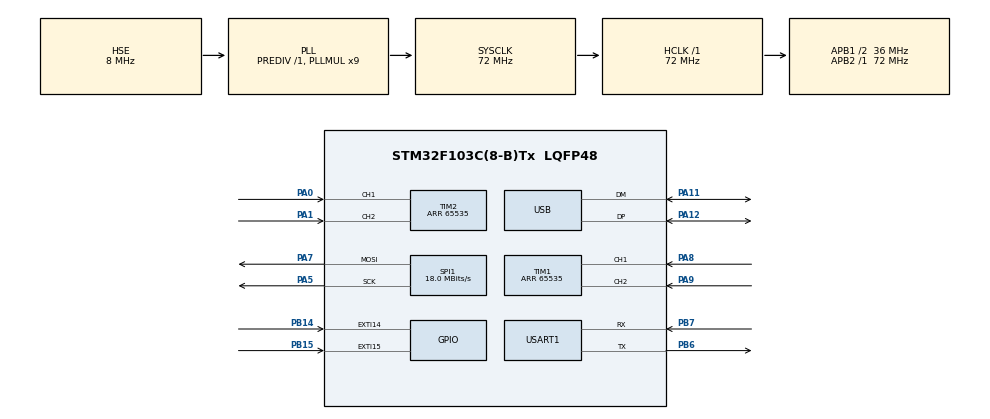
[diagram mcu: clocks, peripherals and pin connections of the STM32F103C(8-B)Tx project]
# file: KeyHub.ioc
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Mcu.Family=STM32F1
Mcu.Name=STM32F103C(8-B)Tx
Mcu.Package=LQFP48
NVIC.EXTI15_10_IRQn=true\:0\:0\:false\:true\:true\:1\:true
NVIC.PriorityGroup=NVIC_PRIORITYGROUP_4
NVIC.USB_HP_CAN1_TX_IRQn=true\:0\:0\:false\:false\:true\:true
NVIC.USB_LP_CAN1_RX0_IRQn=true\:0\:0\:false\:true\:true\:2\:false
PA0-WKUP.GPIO_PuPd=GPIO_PULLUP
PA0-WKUP.Signal=S_TIM2_CH1_ETR
PA1.GPIO_PuPd=GPIO_PULLUP
PA1.Signal=S_TIM2_CH2
PA11.Mode=Device
PA11.Signal=USB_DM
PA12.Mode=Device
PA12.Signal=USB_DP
PA13.Mode=Serial_Wire
PA13.Signal=SYS_JTMS-SWDIO
PA14.Mode=Serial_Wire
PA14.Signal=SYS_JTCK-SWCLK
PA5.Mode=TX_Only_Simplex_Unidirect_Master
PA5.Signal=SPI1_SCK
PA7.Mode=TX_Only_Simplex_Unidirect_Master
PA7.Signal=SPI1_MOSI
PA8.GPIO_PuPd=GPIO_PULLUP
PA8.Signal=S_TIM1_CH1
PA9.GPIO_PuPd=GPIO_PULLUP
PA9.Signal=S_TIM1_CH2
PB14.GPIO_PuPd=GPIO_PULLUP
PB14.Signal=GPXTI14
PB15.GPIO_PuPd=GPIO_PULLUP
PB15.Signal=GPXTI15
PB6.Mode=Asynchronous
PB6.Signal=USART1_TX
PB7.Mode=Asynchronous
PB7.Signal=USART1_RX
PD0-OSC_IN.Mode=HSE-External-Oscillator
PD0-OSC_IN.Signal=RCC_OSC_IN
PD1-OSC_OUT.Mode=HSE-External-Oscillator
PD1-OSC_OUT.Signal=RCC_OSC_OUT
ProjectManager.HeapSize=0x200
ProjectManager.StackSize=0x400
ProjectManager.TargetToolchain=SW4STM32
RCC.AHBFreq_Value=72000000
RCC.APB1CLKDivider=RCC_HCLK_DIV2
RCC.APB1Freq_Value=36000000
RCC.APB1TimFreq_Value=72000000
RCC.APB2Freq_Value=72000000
RCC.APB2TimFreq_Value=72000000
RCC.HCLKFreq_Value=72000000
RCC.PLLMUL=RCC_PLL_MUL9
RCC.SYSCLKFreq_VALUE=72000000
RCC.SYSCLKSource=RCC_SYSCLKSOURCE_PLLCLK
RCC.USBFreq_Value=48000000
RCC.USBPrescaler=RCC_USBCLKSOURCE_PLL_DIV1_5
SH.S_TIM1_CH1.0=TIM1_CH1,Encoder_Interface
SH.S_TIM1_CH2.0=TIM1_CH2,Encoder_Interface
SH.S_TIM2_CH1_ETR.0=TIM2_CH1,Encoder_Interface
SH.S_TIM2_CH2.0=TIM2_CH2,Encoder_Interface
SPI1.BaudRatePrescaler=SPI_BAUDRATEPRESCALER_4
SPI1.CalculateBaudRate=18.0 MBits/s
SPI1.Direction=SPI_DIRECTION_2LINES
SPI1.Mode=SPI_MODE_MASTER
SPI1.VirtualType=VM_MASTER
TIM1.CounterMode=TIM_COUNTERMODE_UP
TIM1.EncoderMode=TIM_ENCODERMODE_TI12
TIM1.IC1Filter=10
TIM1.IC1Polarity=TIM_ICPOLARITY_RISING
TIM1.IC2Filter=0
TIM1.IC2Polarity=TIM_ICPOLARITY_RISING
TIM1.Period=65535
TIM2.EncoderMode=TIM_ENCODERMODE_TI12
TIM2.IC1Filter=10
TIM2.Period=65535
USART1.VirtualMode=VM_ASYNC
USB_DEVICE.CLASS_NAME_FS=CUSTOMHID
USB_DEVICE.VirtualMode=CustomHid
USB_DEVICE.VirtualModeFS=Custom_Hid_FS
VP_USB_DEVICE_VS_USB_DEVICE_CUSTOM_HID_FS.Mode=CUSTOM_HID_FS
board=custom

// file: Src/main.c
/**
  ******************************************************************************
  * @file           : main.c
  * @brief          : Main program body
  ******************************************************************************
  * This notice applies to any and all portions of this file
  * that are not between comment pairs USER CODE BEGIN and
  * USER CODE END. Other portions of this file, whether
  * inserted by the user or by software development tools
  * are owned by their respective copyright owners.
  *
  * Copyright (c) 2021 STMicroelectronics International N.V.
  * All rights reserved.
  *
  * Redistribution and use in source and binary forms, with or without
  * modification, are permitted, provided that the following conditions are met:
  *
  * 1. Redistribution of source code must retain the above copyright notice,
  *    this list of conditions and the following disclaimer.
  * 2. Redistributions in binary form must reproduce the above copyright notice,
  *    this list of conditions and the following disclaimer in the documentation
  *    and/or other materials provided with the distribution.
  * 3. Neither the name of STMicroelectronics nor the names of other
  *    contributors to this software may be used to endorse or promote products
  *    derived from this software without specific written permission.
  * 4. This software, including modifications and/or derivative works of this
  *    software, must execute solely and exclusively on microcontroller or
  *    microprocessor devices manufactured by or for STMicroelectronics.
  * 5. Redistribution and use of this software other than as permitted under
  *    this license is void and will automatically terminate your rights under
  *    this license.
  *
  * THIS SOFTWARE IS PROVIDED BY STMICROELECTRONICS AND CONTRIBUTORS "AS IS"
  * AND ANY EXPRESS, IMPLIED OR STATUTORY WARRANTIES, INCLUDING, BUT NOT
  * LIMITED TO, THE IMPLIED WARRANTIES OF MERCHANTABILITY, FITNESS FOR A
  * PARTICULAR PURPOSE AND NON-INFRINGEMENT OF THIRD PARTY INTELLECTUAL PROPERTY
  * RIGHTS ARE DISCLAIMED TO THE FULLEST EXTENT PERMITTED BY LAW. IN NO EVENT
  * SHALL STMICROELECTRONICS OR CONTRIBUTORS BE LIABLE FOR ANY DIRECT, INDIRECT,
  * INCIDENTAL, SPECIAL, EXEMPLARY, OR CONSEQUENTIAL DAMAGES (INCLUDING, BUT NOT
  * LIMITED TO, PROCUREMENT OF SUBSTITUTE GOODS OR SERVICES; LOSS OF USE, DATA,
  * OR PROFITS; OR BUSINESS INTERRUPTION) HOWEVER CAUSED AND ON ANY THEORY OF
  * LIABILITY, WHETHER IN CONTRACT, STRICT LIABILITY, OR TORT (INCLUDING
  * NEGLIGENCE OR OTHERWISE) ARISING IN ANY WAY OUT OF THE USE OF THIS SOFTWARE,
  * EVEN IF ADVISED OF THE POSSIBILITY OF SUCH DAMAGE.
  *
  ******************************************************************************
  */
#include "main.h"
#include "stm32f1xx_hal.h"
#include "usb_device.h"

SPI_HandleTypeDef hspi1;

TIM_HandleTypeDef htim1;
TIM_HandleTypeDef htim2;

UART_HandleTypeDef huart1;

/* USER CODE BEGIN PV */
/* Private variables ---------------------------------------------------------*/

/* USER CODE END PV */

void SystemClock_Config(void);
static void MX_GPIO_Init(void);
static void MX_SPI1_Init(void);
static void MX_TIM1_Init(void);
static void MX_TIM2_Init(void);
static void MX_USART1_UART_Init(void);
static void MX_NVIC_Init(void);

/* USER CODE BEGIN PFP */
/* Private function prototypes -----------------------------------------------*/

/* USER CODE END PFP */

int main(void)
{
  /* USER CODE BEGIN 1 */
	int8_t OutVal[9] = {'\0'};
	volatile int EncVal;
  /* USER CODE END 1 */

  /* MCU Configuration----------------------------------------------------------*/

  /* Reset of all peripherals, Initializes the Flash interface and the Systick. */
  HAL_Init();

  /* Configure the system clock */
  SystemClock_Config();

  /* Initialize all configured peripherals */
  MX_GPIO_Init();
  MX_SPI1_Init();
  MX_USB_DEVICE_Init();
  MX_TIM1_Init();
  MX_TIM2_Init();
  MX_USART1_UART_Init();

  /* Initialize interrupts */
  MX_NVIC_Init();
  /* USER CODE BEGIN 2 */
  HAL_TIM_Encoder_Start(&htim1, TIM_CHANNEL_ALL);
  /* USER CODE END 2 */

  /* Infinite loop */
  while (1)
  {

  /* USER CODE BEGIN 3 */

	  EncVal = (TIM1->CNT)>>2;
	  sprintf(OutVal, "ABC:%d", EncVal);
	  //EncVal = (TIM1->CNT)>>2;
	  //printf("Encoder -> %d \n\r", EncVal);
	  if(HAL_GPIO_ReadPin(GPIOB, GPIO_PIN_15) == 0)
	  {
		  HAL_UART_Transmit(&huart1, OutVal, sizeof(OutVal), 100);
		  HAL_Delay(500);
	  }

  }
  /* USER CODE END 3 */

}

void SystemClock_Config(void)
{

  RCC_OscInitTypeDef RCC_OscInitStruct;
  RCC_ClkInitTypeDef RCC_ClkInitStruct;
  RCC_PeriphCLKInitTypeDef PeriphClkInit;

    /**Initializes the CPU, AHB and APB busses clocks
    */
  RCC_OscInitStruct.OscillatorType = RCC_OSCILLATORTYPE_HSE;
  RCC_OscInitStruct.HSEState = RCC_HSE_ON;
  RCC_OscInitStruct.HSEPredivValue = RCC_HSE_PREDIV_DIV1;
  RCC_OscInitStruct.HSIState = RCC_HSI_ON;
  RCC_OscInitStruct.PLL.PLLState = RCC_PLL_ON;
  RCC_OscInitStruct.PLL.PLLSource = RCC_PLLSOURCE_HSE;
  RCC_OscInitStruct.PLL.PLLMUL = RCC_PLL_MUL9;
  if (HAL_RCC_OscConfig(&RCC_OscInitStruct) != HAL_OK)
  {
    _Error_Handler(__FILE__, __LINE__);
  }

    /**Initializes the CPU, AHB and APB busses clocks
    */
  RCC_ClkInitStruct.ClockType = RCC_CLOCKTYPE_HCLK|RCC_CLOCKTYPE_SYSCLK
                              |RCC_CLOCKTYPE_PCLK1|RCC_CLOCKTYPE_PCLK2;
  RCC_ClkInitStruct.SYSCLKSource = RCC_SYSCLKSOURCE_PLLCLK;
  RCC_ClkInitStruct.AHBCLKDivider = RCC_SYSCLK_DIV1;
  RCC_ClkInitStruct.APB1CLKDivider = RCC_HCLK_DIV2;
  RCC_ClkInitStruct.APB2CLKDivider = RCC_HCLK_DIV1;

  if (HAL_RCC_ClockConfig(&RCC_ClkInitStruct, FLASH_LATENCY_2) != HAL_OK)
  {
    _Error_Handler(__FILE__, __LINE__);
  }

  PeriphClkInit.PeriphClockSelection = RCC_PERIPHCLK_USB;
  PeriphClkInit.UsbClockSelection = RCC_USBCLKSOURCE_PLL_DIV1_5;
  if (HAL_RCCEx_PeriphCLKConfig(&PeriphClkInit) != HAL_OK)
  {
    _Error_Handler(__FILE__, __LINE__);
  }

    /**Configure the Systick interrupt time
    */
  HAL_SYSTICK_Config(HAL_RCC_GetHCLKFreq()/1000);

    /**Configure the Systick
    */
  HAL_SYSTICK_CLKSourceConfig(SYSTICK_CLKSOURCE_HCLK);

  /* SysTick_IRQn interrupt configuration */
  HAL_NVIC_SetPriority(SysTick_IRQn, 0, 0);
}

/**
  * @brief NVIC Configuration.
  * @retval None
  */
static void MX_NVIC_Init(void)
{
  /* EXTI15_10_IRQn interrupt configuration */
  HAL_NVIC_SetPriority(EXTI15_10_IRQn, 0, 0);
  HAL_NVIC_EnableIRQ(EXTI15_10_IRQn);
  /* USB_LP_CAN1_RX0_IRQn interrupt configuration */
  HAL_NVIC_SetPriority(USB_LP_CAN1_RX0_IRQn, 0, 0);
  HAL_NVIC_EnableIRQ(USB_LP_CAN1_RX0_IRQn);
}

/* SPI1 init function */
static void MX_SPI1_Init(void)
{

  /* SPI1 parameter configuration*/
  hspi1.Instance = SPI1;
  hspi1.Init.Mode = SPI_MODE_MASTER;
  hspi1.Init.Direction = SPI_DIRECTION_2LINES;
  hspi1.Init.DataSize = SPI_DATASIZE_8BIT;
  hspi1.Init.CLKPolarity = SPI_POLARITY_LOW;
  hspi1.Init.CLKPhase = SPI_PHASE_1EDGE;
  hspi1.Init.NSS = SPI_NSS_SOFT;
  hspi1.Init.BaudRatePrescaler = SPI_BAUDRATEPRESCALER_4;
  hspi1.Init.FirstBit = SPI_FIRSTBIT_MSB;
  hspi1.Init.TIMode = SPI_TIMODE_DISABLE;
  hspi1.Init.CRCCalculation = SPI_CRCCALCULATION_DISABLE;
  hspi1.Init.CRCPolynomial = 10;
  if (HAL_SPI_Init(&hspi1) != HAL_OK)
  {
    _Error_Handler(__FILE__, __LINE__);
  }

}

/* TIM1 init function */
static void MX_TIM1_Init(void)
{

  TIM_Encoder_InitTypeDef sConfig;
  TIM_MasterConfigTypeDef sMasterConfig;

  htim1.Instance = TIM1;
  htim1.Init.Prescaler = 0;
  htim1.Init.CounterMode = TIM_COUNTERMODE_UP;
  htim1.Init.Period = 65535;
  htim1.Init.ClockDivision = TIM_CLOCKDIVISION_DIV1;
  htim1.Init.RepetitionCounter = 0;
  htim1.Init.AutoReloadPreload = TIM_AUTORELOAD_PRELOAD_DISABLE;
  sConfig.EncoderMode = TIM_ENCODERMODE_TI12;
  sConfig.IC1Polarity = TIM_ICPOLARITY_RISING;
  sConfig.IC1Selection = TIM_ICSELECTION_DIRECTTI;
  sConfig.IC1Prescaler = TIM_ICPSC_DIV1;
  sConfig.IC1Filter = 10;
  sConfig.IC2Polarity = TIM_ICPOLARITY_RISING;
  sConfig.IC2Selection = TIM_ICSELECTION_DIRECTTI;
  sConfig.IC2Prescaler = TIM_ICPSC_DIV1;
  sConfig.IC2Filter = 0;
  if (HAL_TIM_Encoder_Init(&htim1, &sConfig) != HAL_OK)
  {
    _Error_Handler(__FILE__, __LINE__);
  }

  sMasterConfig.MasterOutputTrigger = TIM_TRGO_RESET;
  sMasterConfig.MasterSlaveMode = TIM_MASTERSLAVEMODE_DISABLE;
  if (HAL_TIMEx_MasterConfigSynchronization(&htim1, &sMasterConfig) != HAL_OK)
  {
    _Error_Handler(__FILE__, __LINE__);
  }

}

/* TIM2 init function */
static void MX_TIM2_Init(void)
{

  TIM_Encoder_InitTypeDef sConfig;
  TIM_MasterConfigTypeDef sMasterConfig;

  htim2.Instance = TIM2;
  htim2.Init.Prescaler = 0;
  htim2.Init.CounterMode = TIM_COUNTERMODE_UP;
  htim2.Init.Period = 65535;
  htim2.Init.ClockDivision = TIM_CLOCKDIVISION_DIV1;
  htim2.Init.AutoReloadPreload = TIM_AUTORELOAD_PRELOAD_DISABLE;
  sConfig.EncoderMode = TIM_ENCODERMODE_TI12;
  sConfig.IC1Polarity = TIM_ICPOLARITY_RISING;
  sConfig.IC1Selection = TIM_ICSELECTION_DIRECTTI;
  sConfig.IC1Prescaler = TIM_ICPSC_DIV1;
  sConfig.IC1Filter = 10;
  sConfig.IC2Polarity = TIM_ICPOLARITY_RISING;
  sConfig.IC2Selection = TIM_ICSELECTION_DIRECTTI;
  sConfig.IC2Prescaler = TIM_ICPSC_DIV1;
  sConfig.IC2Filter = 0;
  if (HAL_TIM_Encoder_Init(&htim2, &sConfig) != HAL_OK)
  {
    _Error_Handler(__FILE__, __LINE__);
  }

  sMasterConfig.MasterOutputTrigger = TIM_TRGO_RESET;
  sMasterConfig.MasterSlaveMode = TIM_MASTERSLAVEMODE_DISABLE;
  if (HAL_TIMEx_MasterConfigSynchronization(&htim2, &sMasterConfig) != HAL_OK)
  {
    _Error_Handler(__FILE__, __LINE__);
  }

}

/* USART1 init function */
static void MX_USART1_UART_Init(void)
{

  huart1.Instance = USART1;
  huart1.Init.BaudRate = 115200;
  huart1.Init.WordLength = UART_WORDLENGTH_8B;
  huart1.Init.StopBits = UART_STOPBITS_1;
  huart1.Init.Parity = UART_PARITY_NONE;
  huart1.Init.Mode = UART_MODE_TX_RX;
  huart1.Init.HwFlowCtl = UART_HWCONTROL_NONE;
  huart1.Init.OverSampling = UART_OVERSAMPLING_16;
  if (HAL_UART_Init(&huart1) != HAL_OK)
  {
    _Error_Handler(__FILE__, __LINE__);
  }

}

/** Configure pins as
        * Analog
        * Input
        * Output
        * EVENT_OUT
        * EXTI
*/
static void MX_GPIO_Init(void)
{

  GPIO_InitTypeDef GPIO_InitStruct;

  /* GPIO Ports Clock Enable */
  __HAL_RCC_GPIOD_CLK_ENABLE();
  __HAL_RCC_GPIOA_CLK_ENABLE();
  __HAL_RCC_GPIOB_CLK_ENABLE();

  /*Configure GPIO pins : PB14 PB15 */
  GPIO_InitStruct.Pin = GPIO_PIN_14|GPIO_PIN_15;
  GPIO_InitStruct.Mode = GPIO_MODE_IT_RISING;
  GPIO_InitStruct.Pull = GPIO_PULLUP;
  HAL_GPIO_Init(GPIOB, &GPIO_InitStruct);

}

void _Error_Handler(char *file, int line)
{
  while(1)
  {
  }
}

/************************ (C) COPYRIGHT STMicroelectronics *****END OF FILE****/
